VERSION ""

NS_ :

BS_:

BU_:

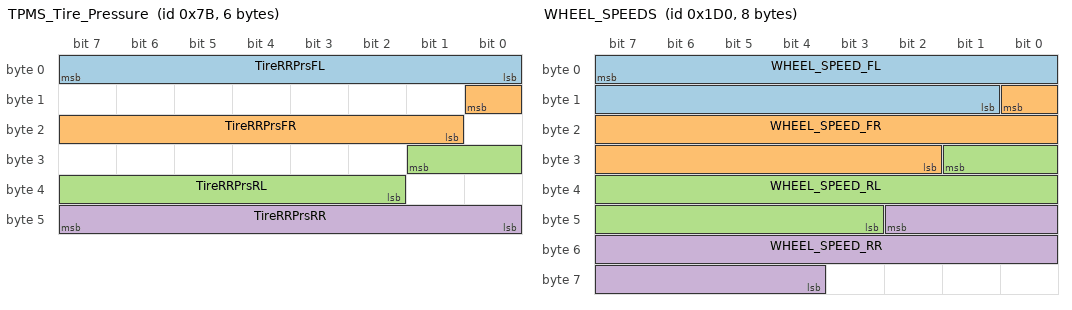
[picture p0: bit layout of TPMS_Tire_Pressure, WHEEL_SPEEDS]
BO_ 123 TPMS_Tire_Pressure: 6 Vector__XXX
 SG_ TireRRPrsFL : 7|8@0+ (4,0) [0|1020] "kPaG" Vector__XXX
 SG_ TireRRPrsFR : 8|8@0+ (4,0) [0|1020] "kPaG" Vector__XXX
 SG_ TireRRPrsRL : 25|8@0+ (4,0) [0|1020] "kPaG" Vector__XXX
 SG_ TireRRPrsRR : 47|8@0+ (4,0) [0|1020] "kPaG" Vector__XXX

BO_ 456 OAT_Outside_Air_Temperature: 8 Vector__XXX
 SG_ OtsAirTmp : 31|8@0+ (0.5,-40) [-40|87.5] "deg C" Vector__XXX

BO_ 532 ABS: 6 Vector__XXX
 SG_ BrakePedalPressure : 0|8@0+ (75,0) [0|19125] "kPa" Vector__XXX

BO_ 401 ECM: 8 Vector__XXX
 SG_ EngineTorque : 3|12@0+ (0.5,-848) [-848|1199.5] "Nm" Vector__XXX

BO_ 464 WHEEL_SPEEDS: 8 VSA
 SG_ WHEEL_SPEED_FL : 7|15@0+ (0.01,0) [0|250] "kph" EON
 SG_ WHEEL_SPEED_FR : 8|15@0+ (0.01,0) [0|250] "kph" EON
 SG_ WHEEL_SPEED_RL : 25|15@0+ (0.01,0) [0|250] "kph" EON
 SG_ WHEEL_SPEED_RR : 42|15@0+ (0.01,0) [0|250] "kph" EON

BA_DEF_ BO_  "GenMsgCycleTime" INT 0 10000;
BA_DEF_DEF_  "GenMsgCycleTime" 0;
BA_ "GenMsgCycleTime" BO_ 123 12;
BA_ "GenMsgCycleTime" BO_ 401 12;
BA_ "GenMsgCycleTime" BO_ 456 50;
BA_ "GenMsgCycleTime" BO_ 464 50;
BA_ "GenMsgCycleTime" BO_ 532 50;
